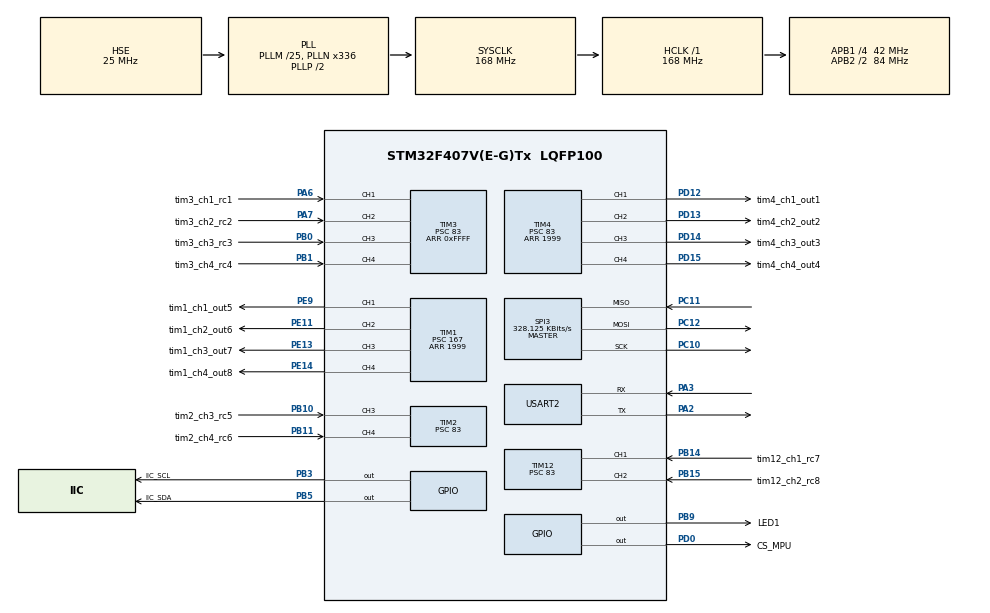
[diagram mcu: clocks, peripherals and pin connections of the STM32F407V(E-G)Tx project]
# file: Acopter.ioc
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Dma.Request0=USART2_RX
Dma.Request1=USART2_TX
Dma.Request2=SPI3_RX
Dma.Request3=SPI3_TX
Dma.SPI3_RX.2.Direction=DMA_PERIPH_TO_MEMORY
Dma.SPI3_RX.2.FIFOMode=DMA_FIFOMODE_DISABLE
Dma.SPI3_RX.2.Instance=DMA1_Stream2
Dma.SPI3_RX.2.MemDataAlignment=DMA_MDATAALIGN_BYTE
Dma.SPI3_RX.2.MemInc=DMA_MINC_ENABLE
Dma.SPI3_RX.2.Mode=DMA_NORMAL
Dma.SPI3_RX.2.PeriphDataAlignment=DMA_PDATAALIGN_BYTE
Dma.SPI3_RX.2.PeriphInc=DMA_PINC_DISABLE
Dma.SPI3_RX.2.Priority=DMA_PRIORITY_HIGH
Dma.SPI3_TX.3.Direction=DMA_MEMORY_TO_PERIPH
Dma.SPI3_TX.3.FIFOMode=DMA_FIFOMODE_DISABLE
Dma.SPI3_TX.3.Instance=DMA1_Stream7
Dma.SPI3_TX.3.MemDataAlignment=DMA_MDATAALIGN_BYTE
Dma.SPI3_TX.3.MemInc=DMA_MINC_ENABLE
Dma.SPI3_TX.3.Mode=DMA_NORMAL
Dma.SPI3_TX.3.PeriphDataAlignment=DMA_PDATAALIGN_BYTE
Dma.SPI3_TX.3.PeriphInc=DMA_PINC_DISABLE
Dma.SPI3_TX.3.Priority=DMA_PRIORITY_LOW
Dma.USART2_RX.0.Direction=DMA_PERIPH_TO_MEMORY
Dma.USART2_RX.0.FIFOMode=DMA_FIFOMODE_DISABLE
Dma.USART2_RX.0.Instance=DMA1_Stream5
Dma.USART2_RX.0.MemDataAlignment=DMA_MDATAALIGN_BYTE
Dma.USART2_RX.0.MemInc=DMA_MINC_ENABLE
Dma.USART2_RX.0.Mode=DMA_NORMAL
Dma.USART2_RX.0.PeriphDataAlignment=DMA_PDATAALIGN_BYTE
Dma.USART2_RX.0.PeriphInc=DMA_PINC_DISABLE
Dma.USART2_RX.0.Priority=DMA_PRIORITY_LOW
Dma.USART2_TX.1.Direction=DMA_MEMORY_TO_PERIPH
Dma.USART2_TX.1.FIFOMode=DMA_FIFOMODE_DISABLE
Dma.USART2_TX.1.Instance=DMA1_Stream6
Dma.USART2_TX.1.MemDataAlignment=DMA_MDATAALIGN_BYTE
Dma.USART2_TX.1.MemInc=DMA_MINC_ENABLE
Dma.USART2_TX.1.Mode=DMA_NORMAL
Dma.USART2_TX.1.PeriphDataAlignment=DMA_PDATAALIGN_BYTE
Dma.USART2_TX.1.PeriphInc=DMA_PINC_DISABLE
Dma.USART2_TX.1.Priority=DMA_PRIORITY_LOW
Mcu.Family=STM32F4
Mcu.Name=STM32F407V(E-G)Tx
Mcu.Package=LQFP100
NVIC.DMA1_Stream2_IRQn=true\:0\:0\:false\:false\:true\:true\:true
NVIC.DMA1_Stream5_IRQn=true\:0\:0\:false\:false\:true\:true\:true
NVIC.DMA1_Stream6_IRQn=true\:0\:0\:false\:false\:true\:true\:true
NVIC.DMA1_Stream7_IRQn=true\:0\:0\:false\:false\:true\:true\:true
NVIC.PriorityGroup=NVIC_PRIORITYGROUP_4
NVIC.SPI3_IRQn=true\:0\:0\:false\:false\:true\:true\:true
NVIC.TIM2_IRQn=true\:0\:0\:false\:false\:true\:true\:true
NVIC.TIM3_IRQn=true\:0\:0\:false\:false\:true\:true\:true
NVIC.TIM8_BRK_TIM12_IRQn=true\:0\:0\:false\:false\:true\:true\:true
NVIC.USART2_IRQn=true\:0\:0\:false\:false\:true\:true\:true
PA2.Mode=Asynchronous
PA2.Signal=USART2_TX
PA3.Mode=Asynchronous
PA3.Signal=USART2_RX
PA6.GPIO_Label=tim3_ch1_rc1
PA6.Signal=S_TIM3_CH1
PA7.GPIO_Label=tim3_ch2_rc2
PA7.Signal=S_TIM3_CH2
PB0.GPIO_Label=tim3_ch3_rc3
PB0.Signal=S_TIM3_CH3
PB1.GPIO_Label=tim3_ch4_rc4
PB1.Signal=S_TIM3_CH4
PB10.GPIO_Label=tim2_ch3_rc5
PB10.Signal=S_TIM2_CH3
PB11.GPIO_Label=tim2_ch4_rc6
PB11.Signal=S_TIM2_CH4
PB14.GPIO_Label=tim12_ch1_rc7
PB14.Signal=S_TIM12_CH1
PB15.GPIO_Label=tim12_ch2_rc8
PB15.Signal=S_TIM12_CH2
PB3.GPIO_Label=IIC_SCL
PB3.GPIO_ModeDefaultOutputPP=GPIO_MODE_OUTPUT_OD
PB3.GPIO_PuPd=GPIO_NOPULL
PB3.GPIO_Speed=GPIO_SPEED_FREQ_VERY_HIGH
PB3.PinState=GPIO_PIN_SET
PB3.Signal=GPIO_Output
PB5.GPIO_Label=IIC_SDA
PB5.GPIO_ModeDefaultOutputPP=GPIO_MODE_OUTPUT_OD
PB5.GPIO_PuPd=GPIO_NOPULL
PB5.GPIO_Speed=GPIO_SPEED_FREQ_VERY_HIGH
PB5.PinState=GPIO_PIN_SET
PB5.Signal=GPIO_Output
PB9.GPIO_Label=LED1
PB9.Signal=GPIO_Output
PC10.Mode=Full_Duplex_Master
PC10.Signal=SPI3_SCK
PC11.Mode=Full_Duplex_Master
PC11.Signal=SPI3_MISO
PC12.Mode=Full_Duplex_Master
PC12.Signal=SPI3_MOSI
PD0.GPIO_Label=CS_MPU
PD0.Signal=GPIO_Output
PD12.GPIO_Label=tim4_ch1_out1
PD12.Signal=S_TIM4_CH1
PD13.GPIO_Label=tim4_ch2_out2
PD13.Signal=S_TIM4_CH2
PD14.GPIO_Label=tim4_ch3_out3
PD14.Signal=S_TIM4_CH3
PD15.GPIO_Label=tim4_ch4_out4
PD15.Signal=S_TIM4_CH4
PE11.GPIO_Label=tim1_ch2_out6
PE11.Signal=S_TIM1_CH2
PE13.GPIO_Label=tim1_ch3_out7
PE13.Signal=S_TIM1_CH3
PE14.GPIO_Label=tim1_ch4_out8
PE14.Signal=S_TIM1_CH4
PE9.GPIO_Label=tim1_ch1_out5
PE9.Signal=S_TIM1_CH1
PH0-OSC_IN.Mode=HSE-External-Oscillator
PH0-OSC_IN.Signal=RCC_OSC_IN
PH1-OSC_OUT.Mode=HSE-External-Oscillator
PH1-OSC_OUT.Signal=RCC_OSC_OUT
ProjectManager.HeapSize=0x200
ProjectManager.StackSize=0x400
ProjectManager.TargetToolchain=EWARM V7
RCC.48MHZClocksFreq_Value=84000000
RCC.AHBFreq_Value=168000000
RCC.APB1CLKDivider=RCC_HCLK_DIV4
RCC.APB1Freq_Value=42000000
RCC.APB1TimFreq_Value=84000000
RCC.APB2CLKDivider=RCC_HCLK_DIV2
RCC.APB2Freq_Value=84000000
RCC.APB2TimFreq_Value=168000000
RCC.CortexFreq_Value=168000000
RCC.HCLKFreq_Value=168000000
RCC.HSE_VALUE=25000000
RCC.HSI_VALUE=16000000
RCC.LSE_VALUE=32768
RCC.PLLM=25
RCC.PLLN=336
RCC.PLLSourceVirtual=RCC_PLLSOURCE_HSE
RCC.SYSCLKFreq_VALUE=168000000
RCC.SYSCLKSource=RCC_SYSCLKSOURCE_PLLCLK
RCC.VCOOutputFreq_Value=336000000
SH.S_TIM12_CH1.0=TIM12_CH1,Input_Capture1_from_TI1
SH.S_TIM12_CH2.0=TIM12_CH2,Input_Capture2_from_TI2
SH.S_TIM1_CH1.0=TIM1_CH1,PWM Generation1 CH1
SH.S_TIM1_CH2.0=TIM1_CH2,PWM Generation2 CH2
SH.S_TIM1_CH3.0=TIM1_CH3,PWM Generation3 CH3
SH.S_TIM1_CH4.0=TIM1_CH4,PWM Generation4 CH4
SH.S_TIM2_CH3.0=TIM2_CH3,Input_Capture3_from_TI3
SH.S_TIM2_CH4.0=TIM2_CH4,Input_Capture4_from_TI4
SH.S_TIM3_CH1.0=TIM3_CH1,Input_Capture1_from_TI1
SH.S_TIM3_CH2.0=TIM3_CH2,Input_Capture2_from_TI2
SH.S_TIM3_CH3.0=TIM3_CH3,Input_Capture3_from_TI3
SH.S_TIM3_CH4.0=TIM3_CH4,Input_Capture4_from_TI4
SH.S_TIM4_CH1.0=TIM4_CH1,PWM Generation1 CH1
SH.S_TIM4_CH2.0=TIM4_CH2,PWM Generation2 CH2
SH.S_TIM4_CH3.0=TIM4_CH3,PWM Generation3 CH3
SH.S_TIM4_CH4.0=TIM4_CH4,PWM Generation4 CH4
SPI3.BaudRatePrescaler=SPI_BAUDRATEPRESCALER_128
SPI3.CLKPolarity=SPI_POLARITY_LOW
SPI3.CalculateBaudRate=328.125 KBits/s
SPI3.Direction=SPI_DIRECTION_2LINES
SPI3.Mode=SPI_MODE_MASTER
SPI3.VirtualType=VM_MASTER
TIM1.Channel-PWM\ Generation1\ CH1=TIM_CHANNEL_1
TIM1.Channel-PWM\ Generation2\ CH2=TIM_CHANNEL_2
TIM1.Channel-PWM\ Generation3\ CH3=TIM_CHANNEL_3
TIM1.Channel-PWM\ Generation4\ CH4=TIM_CHANNEL_4
TIM1.Period=1999
TIM1.Prescaler=167
TIM12.Channel-Input_Capture1_from_TI1=TIM_CHANNEL_1
TIM12.Channel-Input_Capture2_from_TI2=TIM_CHANNEL_2
TIM12.ICPolarity_CH1=TIM_INPUTCHANNELPOLARITY_BOTHEDGE
TIM12.ICPolarity_CH2=TIM_INPUTCHANNELPOLARITY_BOTHEDGE
TIM12.Period=0xFFFF
TIM12.Prescaler=83
TIM2.Channel-Input_Capture3_from_TI3=TIM_CHANNEL_3
TIM2.Channel-Input_Capture4_from_TI4=TIM_CHANNEL_4
TIM2.ICPolarity_CH3=TIM_INPUTCHANNELPOLARITY_BOTHEDGE
TIM2.ICPolarity_CH4=TIM_INPUTCHANNELPOLARITY_BOTHEDGE
TIM2.Period=0xFFFF
TIM2.Prescaler=83
TIM3.Channel-Input_Capture1_from_TI1=TIM_CHANNEL_1
TIM3.Channel-Input_Capture2_from_TI2=TIM_CHANNEL_2
TIM3.Channel-Input_Capture3_from_TI3=TIM_CHANNEL_3
TIM3.Channel-Input_Capture4_from_TI4=TIM_CHANNEL_4
TIM3.ICPolarity_CH1=TIM_INPUTCHANNELPOLARITY_BOTHEDGE
TIM3.ICPolarity_CH2=TIM_INPUTCHANNELPOLARITY_BOTHEDGE
TIM3.ICPolarity_CH3=TIM_INPUTCHANNELPOLARITY_BOTHEDGE
TIM3.ICPolarity_CH4=TIM_INPUTCHANNELPOLARITY_BOTHEDGE
TIM3.Period=0xFFFF
TIM3.Prescaler=83
TIM4.Channel-PWM\ Generation1\ CH1=TIM_CHANNEL_1
TIM4.Channel-PWM\ Generation2\ CH2=TIM_CHANNEL_2
TIM4.Channel-PWM\ Generation3\ CH3=TIM_CHANNEL_3
TIM4.Channel-PWM\ Generation4\ CH4=TIM_CHANNEL_4
TIM4.Period=1999
TIM4.Prescaler=83
USART2.VirtualMode=VM_ASYNC
board=Acopter

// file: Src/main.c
/* USER CODE BEGIN Header */
/**
  ******************************************************************************
  * @file           : main.c
  * @brief          : Main program body
  ******************************************************************************
  * @attention
  *
  * <h2><center>&copy; Copyright (c) 2021 STMicroelectronics.
  * All rights reserved.</center></h2>
  *
  * This software component is licensed by ST under BSD 3-Clause license,
  * the "License"; You may not use this file except in compliance with the
  * License. You may obtain a copy of the License at:
  *                        opensource.org/licenses/BSD-3-Clause
  *
  ******************************************************************************
  */
/* USER CODE END Header */
#include "main.h"

/* USER CODE BEGIN Includes */
#include "include.h"
#include "init.h"
#include "time.h"
#include "scheduler.h"
 #include "delay.h"
/* USER CODE END Includes */

SPI_HandleTypeDef hspi3;
DMA_HandleTypeDef hdma_spi3_rx;
DMA_HandleTypeDef hdma_spi3_tx;

TIM_HandleTypeDef htim1;
TIM_HandleTypeDef htim2;
TIM_HandleTypeDef htim3;
TIM_HandleTypeDef htim4;
TIM_HandleTypeDef htim12;

UART_HandleTypeDef huart2;
DMA_HandleTypeDef hdma_usart2_rx;
DMA_HandleTypeDef hdma_usart2_tx;

/* USER CODE BEGIN PV */
/* Private variables ---------------------------------------------------------*/

/* USER CODE END PV */

void SystemClock_Config(void);
static void MX_GPIO_Init(void);
static void MX_DMA_Init(void);
static void MX_SPI3_Init(void);
static void MX_TIM1_Init(void);
static void MX_TIM2_Init(void);
static void MX_TIM3_Init(void);
static void MX_TIM4_Init(void);
static void MX_TIM12_Init(void);
static void MX_USART2_UART_Init(void);
/* USER CODE BEGIN PFP */
/* Private function prototypes -----------------------------------------------*/

/* USER CODE END PFP */

int main(void)
{

  /* MCU Configuration--------------------------------------------------------*/

  /* Reset of all peripherals, Initializes the Flash interface and the Systick. */
  HAL_Init();

  /* Configure the system clock */
  SystemClock_Config();

  /* Initialize all configured peripherals */
  MX_GPIO_Init();
  MX_DMA_Init();
  MX_SPI3_Init();
  MX_TIM1_Init();
  MX_TIM2_Init();
  MX_TIM3_Init();
  MX_TIM4_Init();
  MX_TIM12_Init();
  MX_USART2_UART_Init();
  /* USER CODE BEGIN 2 */
  All_Init();
  /* USER CODE END 2 */

  /* Infinite loop */
  /* USER CODE BEGIN WHILE */
//  while (1)
//  {
    /* USER CODE END WHILE */

    /* USER CODE BEGIN 3 */
//
//  }
  /* USER CODE END 3 */
}

void SystemClock_Config(void)
{
  RCC_OscInitTypeDef RCC_OscInitStruct = {0};
  RCC_ClkInitTypeDef RCC_ClkInitStruct = {0};

  /** Configure the main internal regulator output voltage
  */
  __HAL_RCC_PWR_CLK_ENABLE();
  __HAL_PWR_VOLTAGESCALING_CONFIG(PWR_REGULATOR_VOLTAGE_SCALE1);
  /** Initializes the RCC Oscillators according to the specified parameters
  * in the RCC_OscInitTypeDef structure.
  */
  RCC_OscInitStruct.OscillatorType = RCC_OSCILLATORTYPE_HSE;
  RCC_OscInitStruct.HSEState = RCC_HSE_ON;
  RCC_OscInitStruct.PLL.PLLState = RCC_PLL_ON;
  RCC_OscInitStruct.PLL.PLLSource = RCC_PLLSOURCE_HSE;
  RCC_OscInitStruct.PLL.PLLM = 25;
  RCC_OscInitStruct.PLL.PLLN = 336;
  RCC_OscInitStruct.PLL.PLLP = RCC_PLLP_DIV2;
  RCC_OscInitStruct.PLL.PLLQ = 4;
  if (HAL_RCC_OscConfig(&RCC_OscInitStruct) != HAL_OK)
  {
    Error_Handler();
  }
  /** Initializes the CPU, AHB and APB buses clocks
  */
  RCC_ClkInitStruct.ClockType = RCC_CLOCKTYPE_HCLK|RCC_CLOCKTYPE_SYSCLK
                              |RCC_CLOCKTYPE_PCLK1|RCC_CLOCKTYPE_PCLK2;
  RCC_ClkInitStruct.SYSCLKSource = RCC_SYSCLKSOURCE_PLLCLK;
  RCC_ClkInitStruct.AHBCLKDivider = RCC_SYSCLK_DIV1;
  RCC_ClkInitStruct.APB1CLKDivider = RCC_HCLK_DIV4;
  RCC_ClkInitStruct.APB2CLKDivider = RCC_HCLK_DIV2;

  if (HAL_RCC_ClockConfig(&RCC_ClkInitStruct, FLASH_LATENCY_5) != HAL_OK)
  {
    Error_Handler();
  }
}

static void MX_SPI3_Init(void)
{

  /* SPI3 parameter configuration*/
  hspi3.Instance = SPI3;
  hspi3.Init.Mode = SPI_MODE_MASTER;
  hspi3.Init.Direction = SPI_DIRECTION_2LINES;
  hspi3.Init.DataSize = SPI_DATASIZE_8BIT;
  hspi3.Init.CLKPolarity = SPI_POLARITY_LOW;
  hspi3.Init.CLKPhase = SPI_PHASE_1EDGE;
  hspi3.Init.NSS = SPI_NSS_SOFT;
  hspi3.Init.BaudRatePrescaler = SPI_BAUDRATEPRESCALER_128;
  hspi3.Init.FirstBit = SPI_FIRSTBIT_MSB;
  hspi3.Init.TIMode = SPI_TIMODE_DISABLE;
  hspi3.Init.CRCCalculation = SPI_CRCCALCULATION_DISABLE;
  hspi3.Init.CRCPolynomial = 10;
  if (HAL_SPI_Init(&hspi3) != HAL_OK)
  {
    Error_Handler();
  }

}

static void MX_TIM1_Init(void)
{

  TIM_MasterConfigTypeDef sMasterConfig = {0};
  TIM_OC_InitTypeDef sConfigOC = {0};
  TIM_BreakDeadTimeConfigTypeDef sBreakDeadTimeConfig = {0};

  htim1.Instance = TIM1;
  htim1.Init.Prescaler = 167;
  htim1.Init.CounterMode = TIM_COUNTERMODE_UP;
  htim1.Init.Period = 1999;
  htim1.Init.ClockDivision = TIM_CLOCKDIVISION_DIV1;
  htim1.Init.RepetitionCounter = 0;
  htim1.Init.AutoReloadPreload = TIM_AUTORELOAD_PRELOAD_DISABLE;
  if (HAL_TIM_PWM_Init(&htim1) != HAL_OK)
  {
    Error_Handler();
  }
  sMasterConfig.MasterOutputTrigger = TIM_TRGO_RESET;
  sMasterConfig.MasterSlaveMode = TIM_MASTERSLAVEMODE_DISABLE;
  if (HAL_TIMEx_MasterConfigSynchronization(&htim1, &sMasterConfig) != HAL_OK)
  {
    Error_Handler();
  }
  sConfigOC.OCMode = TIM_OCMODE_PWM1;
  sConfigOC.Pulse = 0;
  sConfigOC.OCPolarity = TIM_OCPOLARITY_HIGH;
  sConfigOC.OCNPolarity = TIM_OCNPOLARITY_HIGH;
  sConfigOC.OCFastMode = TIM_OCFAST_DISABLE;
  sConfigOC.OCIdleState = TIM_OCIDLESTATE_RESET;
  sConfigOC.OCNIdleState = TIM_OCNIDLESTATE_RESET;
  if (HAL_TIM_PWM_ConfigChannel(&htim1, &sConfigOC, TIM_CHANNEL_1) != HAL_OK)
  {
    Error_Handler();
  }
  if (HAL_TIM_PWM_ConfigChannel(&htim1, &sConfigOC, TIM_CHANNEL_2) != HAL_OK)
  {
    Error_Handler();
  }
  if (HAL_TIM_PWM_ConfigChannel(&htim1, &sConfigOC, TIM_CHANNEL_3) != HAL_OK)
  {
    Error_Handler();
  }
  if (HAL_TIM_PWM_ConfigChannel(&htim1, &sConfigOC, TIM_CHANNEL_4) != HAL_OK)
  {
    Error_Handler();
  }
  sBreakDeadTimeConfig.OffStateRunMode = TIM_OSSR_DISABLE;
  sBreakDeadTimeConfig.OffStateIDLEMode = TIM_OSSI_DISABLE;
  sBreakDeadTimeConfig.LockLevel = TIM_LOCKLEVEL_OFF;
  sBreakDeadTimeConfig.DeadTime = 0;
  sBreakDeadTimeConfig.BreakState = TIM_BREAK_DISABLE;
  sBreakDeadTimeConfig.BreakPolarity = TIM_BREAKPOLARITY_HIGH;
  sBreakDeadTimeConfig.AutomaticOutput = TIM_AUTOMATICOUTPUT_DISABLE;
  if (HAL_TIMEx_ConfigBreakDeadTime(&htim1, &sBreakDeadTimeConfig) != HAL_OK)
  {
    Error_Handler();
  }
  HAL_TIM_MspPostInit(&htim1);

}

static void MX_TIM2_Init(void)
{

  TIM_MasterConfigTypeDef sMasterConfig = {0};
  TIM_IC_InitTypeDef sConfigIC = {0};

  htim2.Instance = TIM2;
  htim2.Init.Prescaler = 83;
  htim2.Init.CounterMode = TIM_COUNTERMODE_UP;
  htim2.Init.Period = 0xFFFF;
  htim2.Init.ClockDivision = TIM_CLOCKDIVISION_DIV1;
  htim2.Init.AutoReloadPreload = TIM_AUTORELOAD_PRELOAD_DISABLE;
  if (HAL_TIM_IC_Init(&htim2) != HAL_OK)
  {
    Error_Handler();
  }
  sMasterConfig.MasterOutputTrigger = TIM_TRGO_RESET;
  sMasterConfig.MasterSlaveMode = TIM_MASTERSLAVEMODE_DISABLE;
  if (HAL_TIMEx_MasterConfigSynchronization(&htim2, &sMasterConfig) != HAL_OK)
  {
    Error_Handler();
  }
  sConfigIC.ICPolarity = TIM_INPUTCHANNELPOLARITY_BOTHEDGE;
  sConfigIC.ICSelection = TIM_ICSELECTION_DIRECTTI;
  sConfigIC.ICPrescaler = TIM_ICPSC_DIV1;
  sConfigIC.ICFilter = 0;
  if (HAL_TIM_IC_ConfigChannel(&htim2, &sConfigIC, TIM_CHANNEL_3) != HAL_OK)
  {
    Error_Handler();
  }
  if (HAL_TIM_IC_ConfigChannel(&htim2, &sConfigIC, TIM_CHANNEL_4) != HAL_OK)
  {
    Error_Handler();
  }

}

static void MX_TIM3_Init(void)
{

  TIM_MasterConfigTypeDef sMasterConfig = {0};
  TIM_IC_InitTypeDef sConfigIC = {0};

  htim3.Instance = TIM3;
  htim3.Init.Prescaler = 83;
  htim3.Init.CounterMode = TIM_COUNTERMODE_UP;
  htim3.Init.Period = 0xFFFF;
  htim3.Init.ClockDivision = TIM_CLOCKDIVISION_DIV1;
  htim3.Init.AutoReloadPreload = TIM_AUTORELOAD_PRELOAD_DISABLE;
  if (HAL_TIM_IC_Init(&htim3) != HAL_OK)
  {
    Error_Handler();
  }
  sMasterConfig.MasterOutputTrigger = TIM_TRGO_RESET;
  sMasterConfig.MasterSlaveMode = TIM_MASTERSLAVEMODE_DISABLE;
  if (HAL_TIMEx_MasterConfigSynchronization(&htim3, &sMasterConfig) != HAL_OK)
  {
    Error_Handler();
  }
  sConfigIC.ICPolarity = TIM_INPUTCHANNELPOLARITY_BOTHEDGE;
  sConfigIC.ICSelection = TIM_ICSELECTION_DIRECTTI;
  sConfigIC.ICPrescaler = TIM_ICPSC_DIV1;
  sConfigIC.ICFilter = 0;
  if (HAL_TIM_IC_ConfigChannel(&htim3, &sConfigIC, TIM_CHANNEL_1) != HAL_OK)
  {
    Error_Handler();
  }
  if (HAL_TIM_IC_ConfigChannel(&htim3, &sConfigIC, TIM_CHANNEL_2) != HAL_OK)
  {
    Error_Handler();
  }
  if (HAL_TIM_IC_ConfigChannel(&htim3, &sConfigIC, TIM_CHANNEL_3) != HAL_OK)
  {
    Error_Handler();
  }
  if (HAL_TIM_IC_ConfigChannel(&htim3, &sConfigIC, TIM_CHANNEL_4) != HAL_OK)
  {
    Error_Handler();
  }

}

static void MX_TIM4_Init(void)
{

  TIM_MasterConfigTypeDef sMasterConfig = {0};
  TIM_OC_InitTypeDef sConfigOC = {0};

  htim4.Instance = TIM4;
  htim4.Init.Prescaler = 83;
  htim4.Init.CounterMode = TIM_COUNTERMODE_UP;
  htim4.Init.Period = 1999;
  htim4.Init.ClockDivision = TIM_CLOCKDIVISION_DIV1;
  htim4.Init.AutoReloadPreload = TIM_AUTORELOAD_PRELOAD_DISABLE;
  if (HAL_TIM_PWM_Init(&htim4) != HAL_OK)
  {
    Error_Handler();
  }
  sMasterConfig.MasterOutputTrigger = TIM_TRGO_RESET;
  sMasterConfig.MasterSlaveMode = TIM_MASTERSLAVEMODE_DISABLE;
  if (HAL_TIMEx_MasterConfigSynchronization(&htim4, &sMasterConfig) != HAL_OK)
  {
    Error_Handler();
  }
  sConfigOC.OCMode = TIM_OCMODE_PWM1;
  sConfigOC.Pulse = 0;
  sConfigOC.OCPolarity = TIM_OCPOLARITY_HIGH;
  sConfigOC.OCFastMode = TIM_OCFAST_DISABLE;
  if (HAL_TIM_PWM_ConfigChannel(&htim4, &sConfigOC, TIM_CHANNEL_1) != HAL_OK)
  {
    Error_Handler();
  }
  if (HAL_TIM_PWM_ConfigChannel(&htim4, &sConfigOC, TIM_CHANNEL_2) != HAL_OK)
  {
    Error_Handler();
  }
  if (HAL_TIM_PWM_ConfigChannel(&htim4, &sConfigOC, TIM_CHANNEL_3) != HAL_OK)
  {
    Error_Handler();
  }
  if (HAL_TIM_PWM_ConfigChannel(&htim4, &sConfigOC, TIM_CHANNEL_4) != HAL_OK)
  {
    Error_Handler();
  }
  HAL_TIM_MspPostInit(&htim4);

}

static void MX_TIM12_Init(void)
{

  TIM_IC_InitTypeDef sConfigIC = {0};

  htim12.Instance = TIM12;
  htim12.Init.Prescaler = 83;
  htim12.Init.CounterMode = TIM_COUNTERMODE_UP;
  htim12.Init.Period = 0xFFFF;
  htim12.Init.ClockDivision = TIM_CLOCKDIVISION_DIV1;
  htim12.Init.AutoReloadPreload = TIM_AUTORELOAD_PRELOAD_DISABLE;
  if (HAL_TIM_IC_Init(&htim12) != HAL_OK)
  {
    Error_Handler();
  }
  sConfigIC.ICPolarity = TIM_INPUTCHANNELPOLARITY_BOTHEDGE;
  sConfigIC.ICSelection = TIM_ICSELECTION_DIRECTTI;
  sConfigIC.ICPrescaler = TIM_ICPSC_DIV1;
  sConfigIC.ICFilter = 0;
  if (HAL_TIM_IC_ConfigChannel(&htim12, &sConfigIC, TIM_CHANNEL_1) != HAL_OK)
  {
    Error_Handler();
  }
  if (HAL_TIM_IC_ConfigChannel(&htim12, &sConfigIC, TIM_CHANNEL_2) != HAL_OK)
  {
    Error_Handler();
  }

}

static void MX_USART2_UART_Init(void)
{

  huart2.Instance = USART2;
  huart2.Init.BaudRate = 115200;
  huart2.Init.WordLength = UART_WORDLENGTH_8B;
  huart2.Init.StopBits = UART_STOPBITS_1;
  huart2.Init.Parity = UART_PARITY_NONE;
  huart2.Init.Mode = UART_MODE_TX_RX;
  huart2.Init.HwFlowCtl = UART_HWCONTROL_NONE;
  huart2.Init.OverSampling = UART_OVERSAMPLING_16;
  if (HAL_UART_Init(&huart2) != HAL_OK)
  {
    Error_Handler();
  }

}

static void MX_DMA_Init(void)
{

  /* DMA controller clock enable */
  __HAL_RCC_DMA1_CLK_ENABLE();

  /* DMA interrupt init */
  /* DMA1_Stream2_IRQn interrupt configuration */
  HAL_NVIC_SetPriority(DMA1_Stream2_IRQn, 0, 0);
  HAL_NVIC_EnableIRQ(DMA1_Stream2_IRQn);
  /* DMA1_Stream5_IRQn interrupt configuration */
  HAL_NVIC_SetPriority(DMA1_Stream5_IRQn, 0, 0);
  HAL_NVIC_EnableIRQ(DMA1_Stream5_IRQn);
  /* DMA1_Stream6_IRQn interrupt configuration */
  HAL_NVIC_SetPriority(DMA1_Stream6_IRQn, 0, 0);
  HAL_NVIC_EnableIRQ(DMA1_Stream6_IRQn);
  /* DMA1_Stream7_IRQn interrupt configuration */
  HAL_NVIC_SetPriority(DMA1_Stream7_IRQn, 0, 0);
  HAL_NVIC_EnableIRQ(DMA1_Stream7_IRQn);

}

static void MX_GPIO_Init(void)
{
  GPIO_InitTypeDef GPIO_InitStruct = {0};

  /* GPIO Ports Clock Enable */
  __HAL_RCC_GPIOH_CLK_ENABLE();
  __HAL_RCC_GPIOA_CLK_ENABLE();
  __HAL_RCC_GPIOB_CLK_ENABLE();
  __HAL_RCC_GPIOE_CLK_ENABLE();
  __HAL_RCC_GPIOD_CLK_ENABLE();
  __HAL_RCC_GPIOC_CLK_ENABLE();

  /*Configure GPIO pin Output Level */
  HAL_GPIO_WritePin(CS_MPU_GPIO_Port, CS_MPU_Pin, GPIO_PIN_RESET);

  /*Configure GPIO pin Output Level */
  HAL_GPIO_WritePin(GPIOB, IIC_SCL_Pin|IIC_SDA_Pin, GPIO_PIN_SET);

  /*Configure GPIO pin Output Level */
  HAL_GPIO_WritePin(LED1_GPIO_Port, LED1_Pin, GPIO_PIN_RESET);

  /*Configure GPIO pin : CS_MPU_Pin */
  GPIO_InitStruct.Pin = CS_MPU_Pin;
  GPIO_InitStruct.Mode = GPIO_MODE_OUTPUT_PP;
  GPIO_InitStruct.Pull = GPIO_NOPULL;
  GPIO_InitStruct.Speed = GPIO_SPEED_FREQ_LOW;
  HAL_GPIO_Init(CS_MPU_GPIO_Port, &GPIO_InitStruct);

  /*Configure GPIO pins : IIC_SCL_Pin IIC_SDA_Pin */
  GPIO_InitStruct.Pin = IIC_SCL_Pin|IIC_SDA_Pin;
  GPIO_InitStruct.Mode = GPIO_MODE_OUTPUT_OD;
  GPIO_InitStruct.Pull = GPIO_NOPULL;
  GPIO_InitStruct.Speed = GPIO_SPEED_FREQ_VERY_HIGH;
  HAL_GPIO_Init(GPIOB, &GPIO_InitStruct);

  /*Configure GPIO pin : LED1_Pin */
  GPIO_InitStruct.Pin = LED1_Pin;
  GPIO_InitStruct.Mode = GPIO_MODE_OUTPUT_PP;
  GPIO_InitStruct.Pull = GPIO_NOPULL;
  GPIO_InitStruct.Speed = GPIO_SPEED_FREQ_LOW;
  HAL_GPIO_Init(LED1_GPIO_Port, &GPIO_InitStruct);

}

void Error_Handler(void)
{
  __disable_irq();
  while (1)
  {
  }
}

/************************ (C) COPYRIGHT STMicroelectronics *****END OF FILE****/
